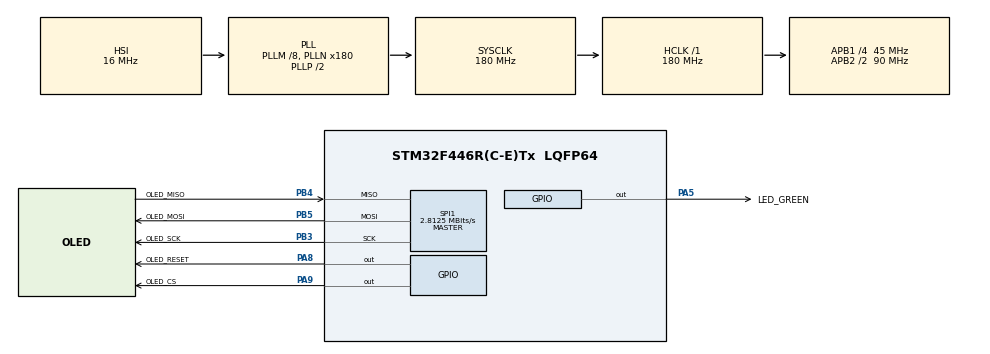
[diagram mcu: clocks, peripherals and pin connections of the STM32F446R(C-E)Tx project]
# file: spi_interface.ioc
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Mcu.Family=STM32F4
Mcu.Name=STM32F446R(C-E)Tx
Mcu.Package=LQFP64
NVIC.PriorityGroup=NVIC_PRIORITYGROUP_4
PA5.GPIO_Label=LED_GREEN
PA5.Signal=GPIO_Output
PA8.GPIO_Label=OLED_RESET
PA8.Signal=GPIO_Output
PA9.GPIO_Label=OLED_CS
PA9.Signal=GPIO_Output
PB3.GPIO_Label=OLED_SCK
PB3.Mode=Full_Duplex_Master
PB3.Signal=SPI1_SCK
PB4.GPIO_Label=OLED_MISO
PB4.Mode=Full_Duplex_Master
PB4.Signal=SPI1_MISO
PB5.GPIO_Label=OLED_MOSI
PB5.Mode=Full_Duplex_Master
PB5.Signal=SPI1_MOSI
ProjectManager.HeapSize=0x200
ProjectManager.StackSize=0x400
ProjectManager.TargetToolchain=STM32CubeIDE
RCC.AHBFreq_Value=180000000
RCC.APB1CLKDivider=RCC_HCLK_DIV4
RCC.APB1Freq_Value=45000000
RCC.APB1TimFreq_Value=90000000
RCC.APB2CLKDivider=RCC_HCLK_DIV2
RCC.APB2Freq_Value=90000000
RCC.APB2TimFreq_Value=180000000
RCC.CortexFreq_Value=180000000
RCC.HCLKFreq_Value=180000000
RCC.PLLM=8
RCC.PLLN=180
RCC.SYSCLKFreq_VALUE=180000000
RCC.SYSCLKSource=RCC_SYSCLKSOURCE_PLLCLK
RCC.USBFreq_Value=180000000
RCC.VCOOutputFreq_Value=360000000
SPI1.BaudRatePrescaler=SPI_BAUDRATEPRESCALER_32
SPI1.CalculateBaudRate=2.8125 MBits/s
SPI1.Direction=SPI_DIRECTION_2LINES
SPI1.Mode=SPI_MODE_MASTER
SPI1.VirtualType=VM_MASTER
board=custom

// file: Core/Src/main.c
/* USER CODE BEGIN Header */
/**
  ******************************************************************************
  * @file           : main.c
  * @brief          : Main program body
  ******************************************************************************
  * @attention
  *
  * <h2><center>&copy; Copyright (c) 2020 STMicroelectronics.
  * All rights reserved.</center></h2>
  *
  * This software component is licensed by ST under BSD 3-Clause license,
  * the "License"; You may not use this file except in compliance with the
  * License. You may obtain a copy of the License at:
  *                        opensource.org/licenses/BSD-3-Clause
  *
  ******************************************************************************
  */
/* USER CODE END Header */
#include "main.h"

SPI_HandleTypeDef hspi1;

void SystemClock_Config(void);
static void MX_GPIO_Init(void);
static void MX_SPI1_Init(void);

/* USER CODE BEGIN 0 */
uint8_t spi_data[2];
/* USER CODE END 0 */

int main(void)
{

  /* MCU Configuration--------------------------------------------------------*/

  /* Reset of all peripherals, Initializes the Flash interface and the Systick. */
  HAL_Init();

  /* Configure the system clock */
  SystemClock_Config();

  /* Initialize all configured peripherals */
  MX_GPIO_Init();
  MX_SPI1_Init();
  /* USER CODE BEGIN 2 */
  // Deactivate slave
  HAL_GPIO_WritePin(GPIOA, GPIO_PIN_9, GPIO_PIN_SET);
  HAL_Delay(10);

  // Read data SPI
  // Activate slave
  HAL_GPIO_WritePin(GPIOA, GPIO_PIN_9, GPIO_PIN_RESET);
  // Transmit register address
  spi_data[0] = 0x05;
  HAL_SPI_Transmit(hspi, spi_data, 1, 10);
  // Read
  HAL_SPI_Receive(hspi, &spi_data[1], 1, 10);
  // Deactivate slave
  HAL_GPIO_WritePin(GPIOA, GPIO_PIN_9, GPIO_PIN_SET);
  HAL_Delay(10);
  /* USER CODE END 2 */

  /* Infinite loop */
  while (1)
  {

  }
}

void SystemClock_Config(void)
{
  RCC_OscInitTypeDef RCC_OscInitStruct = {0};
  RCC_ClkInitTypeDef RCC_ClkInitStruct = {0};

  /** Configure the main internal regulator output voltage
  */
  __HAL_RCC_PWR_CLK_ENABLE();
  __HAL_PWR_VOLTAGESCALING_CONFIG(PWR_REGULATOR_VOLTAGE_SCALE1);
  /** Initializes the RCC Oscillators according to the specified parameters
  * in the RCC_OscInitTypeDef structure.
  */
  RCC_OscInitStruct.OscillatorType = RCC_OSCILLATORTYPE_HSI;
  RCC_OscInitStruct.HSIState = RCC_HSI_ON;
  RCC_OscInitStruct.HSICalibrationValue = RCC_HSICALIBRATION_DEFAULT;
  RCC_OscInitStruct.PLL.PLLState = RCC_PLL_ON;
  RCC_OscInitStruct.PLL.PLLSource = RCC_PLLSOURCE_HSI;
  RCC_OscInitStruct.PLL.PLLM = 8;
  RCC_OscInitStruct.PLL.PLLN = 180;
  RCC_OscInitStruct.PLL.PLLP = RCC_PLLP_DIV2;
  RCC_OscInitStruct.PLL.PLLQ = 2;
  RCC_OscInitStruct.PLL.PLLR = 2;
  if (HAL_RCC_OscConfig(&RCC_OscInitStruct) != HAL_OK)
  {
    Error_Handler();
  }
  /** Activate the Over-Drive mode
  */
  if (HAL_PWREx_EnableOverDrive() != HAL_OK)
  {
    Error_Handler();
  }
  /** Initializes the CPU, AHB and APB buses clocks
  */
  RCC_ClkInitStruct.ClockType = RCC_CLOCKTYPE_HCLK|RCC_CLOCKTYPE_SYSCLK
                              |RCC_CLOCKTYPE_PCLK1|RCC_CLOCKTYPE_PCLK2;
  RCC_ClkInitStruct.SYSCLKSource = RCC_SYSCLKSOURCE_PLLCLK;
  RCC_ClkInitStruct.AHBCLKDivider = RCC_SYSCLK_DIV1;
  RCC_ClkInitStruct.APB1CLKDivider = RCC_HCLK_DIV4;
  RCC_ClkInitStruct.APB2CLKDivider = RCC_HCLK_DIV2;

  if (HAL_RCC_ClockConfig(&RCC_ClkInitStruct, FLASH_LATENCY_5) != HAL_OK)
  {
    Error_Handler();
  }
}

static void MX_SPI1_Init(void)
{

  /* SPI1 parameter configuration*/
  hspi1.Instance = SPI1;
  hspi1.Init.Mode = SPI_MODE_MASTER;
  hspi1.Init.Direction = SPI_DIRECTION_2LINES;
  hspi1.Init.DataSize = SPI_DATASIZE_8BIT;
  hspi1.Init.CLKPolarity = SPI_POLARITY_LOW;
  hspi1.Init.CLKPhase = SPI_PHASE_1EDGE;
  hspi1.Init.NSS = SPI_NSS_SOFT;
  hspi1.Init.BaudRatePrescaler = SPI_BAUDRATEPRESCALER_32;
  hspi1.Init.FirstBit = SPI_FIRSTBIT_MSB;
  hspi1.Init.TIMode = SPI_TIMODE_DISABLE;
  hspi1.Init.CRCCalculation = SPI_CRCCALCULATION_DISABLE;
  hspi1.Init.CRCPolynomial = 10;
  if (HAL_SPI_Init(&hspi1) != HAL_OK)
  {
    Error_Handler();
  }

}

static void MX_GPIO_Init(void)
{
  GPIO_InitTypeDef GPIO_InitStruct = {0};

  /* GPIO Ports Clock Enable */
  __HAL_RCC_GPIOA_CLK_ENABLE();
  __HAL_RCC_GPIOB_CLK_ENABLE();

  /*Configure GPIO pin Output Level */
  HAL_GPIO_WritePin(GPIOA, LED_GREEN_Pin|OLED_RESET_Pin|OLED_CS_Pin, GPIO_PIN_RESET);

  /*Configure GPIO pins : LED_GREEN_Pin OLED_RESET_Pin OLED_CS_Pin */
  GPIO_InitStruct.Pin = LED_GREEN_Pin|OLED_RESET_Pin|OLED_CS_Pin;
  GPIO_InitStruct.Mode = GPIO_MODE_OUTPUT_PP;
  GPIO_InitStruct.Pull = GPIO_NOPULL;
  GPIO_InitStruct.Speed = GPIO_SPEED_FREQ_LOW;
  HAL_GPIO_Init(GPIOA, &GPIO_InitStruct);

}

void Error_Handler(void)
{
}

/************************ (C) COPYRIGHT STMicroelectronics *****END OF FILE****/
